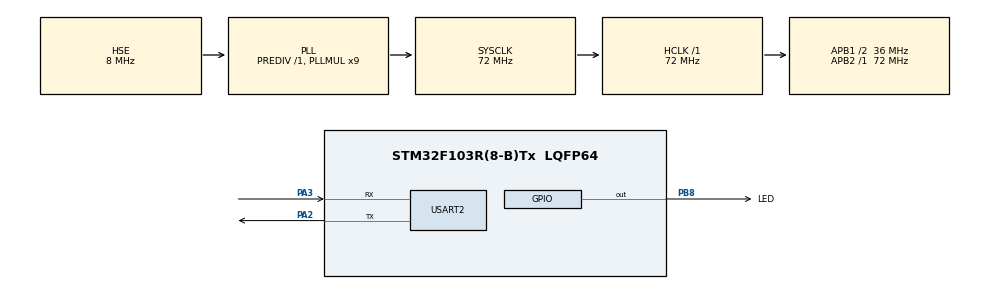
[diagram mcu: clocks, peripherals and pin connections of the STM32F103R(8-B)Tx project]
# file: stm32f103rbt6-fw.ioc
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Mcu.Family=STM32F1
Mcu.Name=STM32F103R(8-B)Tx
Mcu.Package=LQFP64
NVIC.PriorityGroup=NVIC_PRIORITYGROUP_4
NVIC.USART2_IRQn=true\:0\:0\:false\:false\:true\:true\:true\:true
PA2.Mode=Asynchronous
PA2.Signal=USART2_TX
PA3.Mode=Asynchronous
PA3.Signal=USART2_RX
PB8.GPIO_Label=LED
PB8.Signal=GPIO_Output
PD0-OSC_IN.Mode=HSE-External-Oscillator
PD0-OSC_IN.Signal=RCC_OSC_IN
PD1-OSC_OUT.Mode=HSE-External-Oscillator
PD1-OSC_OUT.Signal=RCC_OSC_OUT
ProjectManager.HeapSize=0x200
ProjectManager.StackSize=0x400
ProjectManager.TargetToolchain=MDK-ARM V5
RCC.AHBFreq_Value=72000000
RCC.APB1CLKDivider=RCC_HCLK_DIV2
RCC.APB1Freq_Value=36000000
RCC.APB1TimFreq_Value=72000000
RCC.APB2Freq_Value=72000000
RCC.APB2TimFreq_Value=72000000
RCC.HCLKFreq_Value=72000000
RCC.PLLMUL=RCC_PLL_MUL9
RCC.PLLSourceVirtual=RCC_PLLSOURCE_HSE
RCC.SYSCLKFreq_VALUE=72000000
RCC.SYSCLKSource=RCC_SYSCLKSOURCE_PLLCLK
RCC.USBFreq_Value=72000000
USART2.VirtualMode=VM_ASYNC
VP_SYS_VS_ND.Mode=No_Debug
board=custom

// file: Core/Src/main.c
/* USER CODE BEGIN Header */
/**
 ******************************************************************************
 * @file           : main.c
 * @brief          : Main program body
 ******************************************************************************
 * @attention
 *
 * Copyright (c) 2023 STMicroelectronics.
 * All rights reserved.
 *
 * This software is licensed under terms that can be found in the LICENSE file
 * in the root directory of this software component.
 * If no LICENSE file comes with this software, it is provided AS-IS.
 *
 ******************************************************************************
 */
/* USER CODE END Header */
#include "main.h"

/* USER CODE BEGIN Includes */
#include <stdio.h>
/* USER CODE END Includes */

UART_HandleTypeDef huart2;

void SystemClock_Config(void);
static void MX_GPIO_Init(void);
static void MX_USART2_UART_Init(void);

/* USER CODE BEGIN 0 */
int _write(int fd, char *ch, int len)
{
  HAL_UART_Transmit(&huart2, (uint8_t *)ch, len, 0xFFFF);
  return len;
}

#include <stdarg.h>
int u_printf(const char *format, ...)
{
	char loc_buf[256];
	va_list arg;
	va_list copy;
	va_start(arg, format);
	va_copy(copy, arg);
	int len = vsnprintf(loc_buf, sizeof(loc_buf), format, copy);
	va_end(copy);
	va_end(arg);

	if (len > 0 && len <= 256)
	{
		HAL_UART_Transmit(&huart2, (uint8_t *)loc_buf, len, 0xFF);
	}
	return len;
}

// 串口接收BUFF
uint8_t g_uRxBuf[1] = { 0 };

/* USER CODE END 0 */

int main(void)
{

  /* MCU Configuration--------------------------------------------------------*/

  /* Reset of all peripherals, Initializes the Flash interface and the Systick. */
  HAL_Init();

  /* Configure the system clock */
  SystemClock_Config();

  /* Initialize all configured peripherals */
  MX_GPIO_Init();
  MX_USART2_UART_Init();

  /* Infinite loop */
  /* USER CODE BEGIN WHILE */
  u_printf("hello, stm32f103rbt6\r\n");
  while (1)
  {
    /* USER CODE END WHILE */

    /* USER CODE BEGIN 3 */
    /**********begin**********/
    // u_printf("...\r\n");
    //////////////////////////////////////////////////////////////////// PS: The answer is as follows:
    char data[20] = "Hello, world!\r\n";
    _write(0, data, 15);
    ////////////////////////////////////////////////////////////////////// PS: End of question answer.

    /***********end**********/
    HAL_Delay(1000);
  }
  /* USER CODE END 3 */
}

void SystemClock_Config(void)
{
  RCC_OscInitTypeDef RCC_OscInitStruct = {0};
  RCC_ClkInitTypeDef RCC_ClkInitStruct = {0};

  /** Initializes the RCC Oscillators according to the specified parameters
  * in the RCC_OscInitTypeDef structure.
  */
  RCC_OscInitStruct.OscillatorType = RCC_OSCILLATORTYPE_HSE;
  RCC_OscInitStruct.HSEState = RCC_HSE_ON;
  RCC_OscInitStruct.HSEPredivValue = RCC_HSE_PREDIV_DIV1;
  RCC_OscInitStruct.HSIState = RCC_HSI_ON;
  RCC_OscInitStruct.PLL.PLLState = RCC_PLL_ON;
  RCC_OscInitStruct.PLL.PLLSource = RCC_PLLSOURCE_HSE;
  RCC_OscInitStruct.PLL.PLLMUL = RCC_PLL_MUL9;
  if (HAL_RCC_OscConfig(&RCC_OscInitStruct) != HAL_OK)
  {
    Error_Handler();
  }

  /** Initializes the CPU, AHB and APB buses clocks
  */
  RCC_ClkInitStruct.ClockType = RCC_CLOCKTYPE_HCLK|RCC_CLOCKTYPE_SYSCLK
                              |RCC_CLOCKTYPE_PCLK1|RCC_CLOCKTYPE_PCLK2;
  RCC_ClkInitStruct.SYSCLKSource = RCC_SYSCLKSOURCE_PLLCLK;
  RCC_ClkInitStruct.AHBCLKDivider = RCC_SYSCLK_DIV1;
  RCC_ClkInitStruct.APB1CLKDivider = RCC_HCLK_DIV2;
  RCC_ClkInitStruct.APB2CLKDivider = RCC_HCLK_DIV1;

  if (HAL_RCC_ClockConfig(&RCC_ClkInitStruct, FLASH_LATENCY_2) != HAL_OK)
  {
    Error_Handler();
  }
}

static void MX_USART2_UART_Init(void)
{

  huart2.Instance = USART2;
  huart2.Init.BaudRate = 115200;
  huart2.Init.WordLength = UART_WORDLENGTH_8B;
  huart2.Init.StopBits = UART_STOPBITS_1;
  huart2.Init.Parity = UART_PARITY_NONE;
  huart2.Init.Mode = UART_MODE_TX_RX;
  huart2.Init.HwFlowCtl = UART_HWCONTROL_NONE;
  huart2.Init.OverSampling = UART_OVERSAMPLING_16;
  if (HAL_UART_Init(&huart2) != HAL_OK)
  {
    Error_Handler();
  }
  /* USER CODE BEGIN USART2_Init 2 */
  HAL_UART_Receive_IT(&huart2, g_uRxBuf, sizeof(g_uRxBuf));
  /* USER CODE END USART2_Init 2 */

}

static void MX_GPIO_Init(void)
{
  GPIO_InitTypeDef GPIO_InitStruct = {0};

  /* GPIO Ports Clock Enable */
  __HAL_RCC_GPIOD_CLK_ENABLE();
  __HAL_RCC_GPIOA_CLK_ENABLE();
  __HAL_RCC_GPIOB_CLK_ENABLE();

  /*Configure GPIO pin Output Level */
  HAL_GPIO_WritePin(LED_GPIO_Port, LED_Pin, GPIO_PIN_RESET);

  /*Configure GPIO pin : LED_Pin */
  GPIO_InitStruct.Pin = LED_Pin;
  GPIO_InitStruct.Mode = GPIO_MODE_OUTPUT_PP;
  GPIO_InitStruct.Pull = GPIO_NOPULL;
  GPIO_InitStruct.Speed = GPIO_SPEED_FREQ_LOW;
  HAL_GPIO_Init(LED_GPIO_Port, &GPIO_InitStruct);

}

/* USER CODE BEGIN 4 */

void HAL_UART_RxCpltCallback(UART_HandleTypeDef *huart)
{
  HAL_UART_Transmit(&huart2, g_uRxBuf, sizeof(g_uRxBuf), 0xFF);
  HAL_UART_Receive_IT(&huart2, g_uRxBuf, sizeof(g_uRxBuf));
}

/* USER CODE END 4 */

void Error_Handler(void)
{
  __disable_irq();
  while (1)
  {
  }
}

#ifdef  USE_FULL_ASSERT
/**
  * @brief  Reports the name of the source file and the source line number
  *         where the assert_param error has occurred.
  * @param  file: pointer to the source file name
  * @param  line: assert_param error line source number
  * @retval None
  */
void assert_failed(uint8_t *file, uint32_t line)
{
  /* USER CODE BEGIN 6 */
  /* User can add his own implementation to report the file name and line number,
     ex: printf("Wrong parameters value: file %s on line %d\r\n", file, line) */
  printf("Wrong parameters value: file %s on line %ld\r\n", file, line);
  /* USER CODE END 6 */
}
#endif /* USE_FULL_ASSERT */
